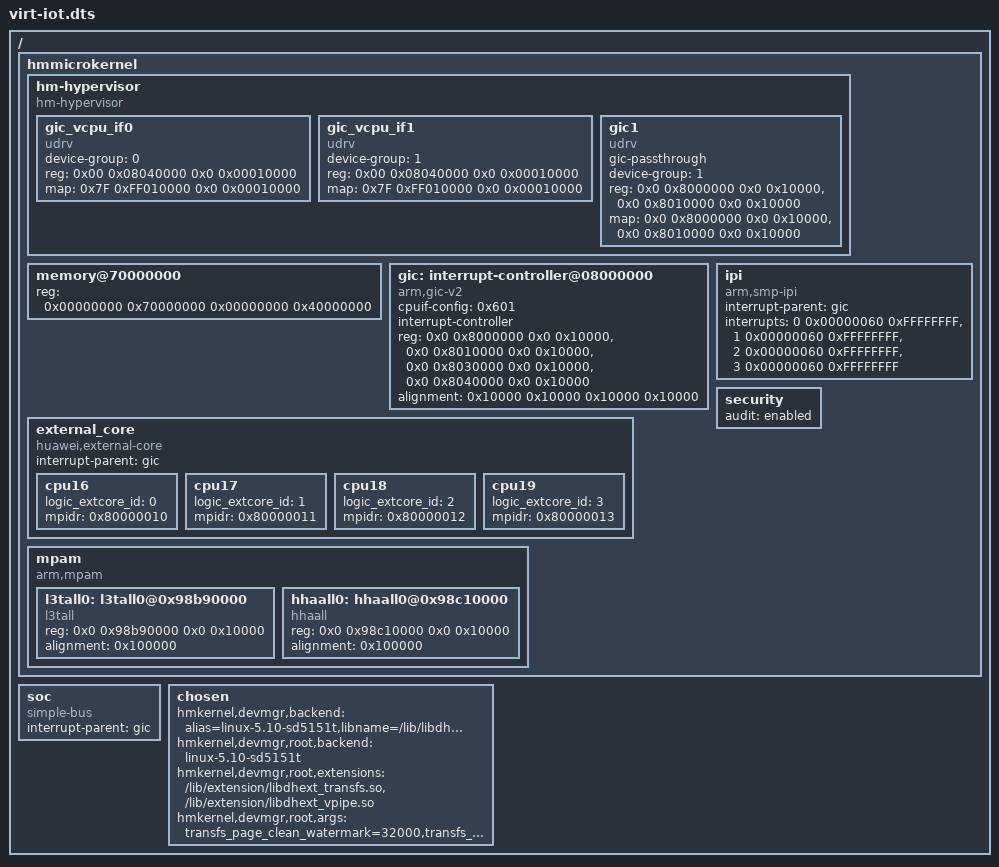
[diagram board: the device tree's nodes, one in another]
/dts-v1/;

/ {
	#address-cells = <2>;
	#size-cells = <2>;

	hmmicrokernel {
		#address-cells = <2>;
		#size-cells = <2>;

		hm-hypervisor {
			compatible = "hm-hypervisor";
			#address-cells = <2>;
			#size-cells = <2>;

			/include/ "virt-iot-common.dtsi"

			/* Add new properties precede the dtsi */
			gic_vcpu_if0 {
				device-group = <0>;
				compatible = "udrv";
				reg = <0x00 0x08040000 0x0 0x00010000>;
				map = <0x7F 0xFF010000 0x0 0x00010000>;
			};

			gic_vcpu_if1 {
				device-group = <1>;
				compatible = "udrv";
				reg = <0x00 0x08040000 0x0 0x00010000>;
				map = <0x7F 0xFF010000 0x0 0x00010000>;
			};

			gic1 {
				compatible = "udrv";
				gic-passthrough;
				device-group = <1>;
				reg =	<0x0 0x8000000 0x0 0x10000>,	/* GICD */
					<0x0 0x8010000 0x0 0x10000>;	/* GICC */
				map =	<0x0 0x8000000 0x0 0x10000>,	/* GICD */
					<0x0 0x8010000 0x0 0x10000>;	/* GICC */
			};
		};

		/*
		 * Enlarge the host memory for iot,
		 * the qemu.run script shuld be modified accordingly.
		 */
		memory@70000000 {
			device_type = "memory";
			reg = <0x00000000 0x70000000 0x00000000 0x40000000>;
		};

		/* See Documentation/dts-gic.md for interrupts and distributor_config */
		gic: interrupt-controller@08000000 {
			compatible = "arm,gic-v2";

			#address-cells = <2>;
			#size-cells = <2>;

			/* enable group 0 & 1, split EOI mode */
			cpuif-config = <0x601>;

			#interrupt-cells = <3>;
			interrupt-controller;

			reg =	<0x0 0x8000000 0x0 0x10000>,	/* GICD */
				<0x0 0x8010000 0x0 0x10000>,	/* GICC */
				<0x0 0x8030000 0x0 0x10000>,	/* GICH */
				<0x0 0x8040000 0x0 0x10000>;	/* GICV */
			alignment = <0x10000 0x10000 0x10000 0x10000>;
		};

		external_core {
			compatible = "huawei,external-core";

			interrupt-parent = <&gic>;

			cpu16 {
				logic_extcore_id = <0>;
				mpidr = <0x80000010>;
			};
			cpu17 {
				logic_extcore_id = <1>;
				mpidr = <0x80000011>;
			};
			cpu18 {
				logic_extcore_id = <2>;
				mpidr = <0x80000012>;
			};
			cpu19 {
				logic_extcore_id = <3>;
				mpidr = <0x80000013>;
			};
		};

		/* MPAM node information
		 * this is a fake node for testcase
		 */
		mpam {
			compatible = "arm,mpam";
			#address-cells = <2>;
			#size-cells = <2>;

			/* L3T: L3 cache, it includes L3 Tag and L3 Data */
			l3tall0: l3tall0@0x98b90000 {
				compatible = "l3tall";
				reg = <0x0 0x98b90000 0x0 0x10000>;
				alignment = <0x100000>;
			};
			/* HHA: hydra home agent. HHA is located between L3T and DDR,
			 * providing the system with a DDR access channel. When the
			 * CPU accesses memory, it reads DDR data through the
			 * corresponding HHA.
			 */
			hhaall0: hhaall0@0x98c10000 {
				compatible = "hhaall";
				reg = <0x0 0x98c10000 0x0 0x10000>;
				alignment = <0x100000>;
			};
		};

		ipi {
			/* smp ipi */
			compatible = "arm,smp-ipi";

			interrupt-parent = <&gic>;

			/* interrupt settings:
			 * 1st cell: real hardware irq number
			 *     ARM recommendation: ID 0-7 for Non-Secure;
			 *                         ID 8-15 for Secure Interrupt
			 * 2nd cell: interrupt config
			 *     bit [27:26]: Group setting
			 *     bit [24]: Trigger Type
			 *     bit [7:0]: Priority
			 * 3rd cell: interrupt target config
			 *     Warning: Send to all cpus by default
			 */
			interrupts =	<0 0x00000060 0xFFFFFFFF>, /* IPI_RESCHEDULE */
					<1 0x00000060 0xFFFFFFFF>, /* IPI_CALL_FUNC */
					<2 0x00000060 0xFFFFFFFF>, /* IPI_CPU_STOP */
					<3 0x00000060 0xFFFFFFFF>; /* IPI_VNOTIFY */
		};

		security {
			audit = "enabled";
		};
	};

	soc {
		compatible = "simple-bus";
		#address-cells = <2>;
		#size-cells = <2>;
		ranges;
		interrupt-parent = <&gic>;
	};

	/* copy from "sd5151t.dts" */
	chosen {
		/* config devhost backend */
		hmkernel,devmgr,backend =
			"alias=linux-5.10-sd5151t,libname=/lib/libdh-linux.so.5.10-sd5151t,modpath=/lib/modules/linux-5.10.0-sd5151t,default";

		/* config root devhost */
		hmkernel,devmgr,root,backend = "linux-5.10-sd5151t";
		hmkernel,devmgr,root,extensions = "/lib/extension/libdhext_transfs.so",
						  "/lib/extension/libdhext_vpipe.so";
		/* note: max limit length of transfs.ko args is 256 */
		hmkernel,devmgr,root,args = "transfs_page_clean_watermark=32000,transfs_page_sync_watermark=34000";
	};

};

/include/ "virtio.dtsi"
/include/ "virt-common.dtsi"
